AUTOSAR XML (schema 00046)
package /ComponentTypes
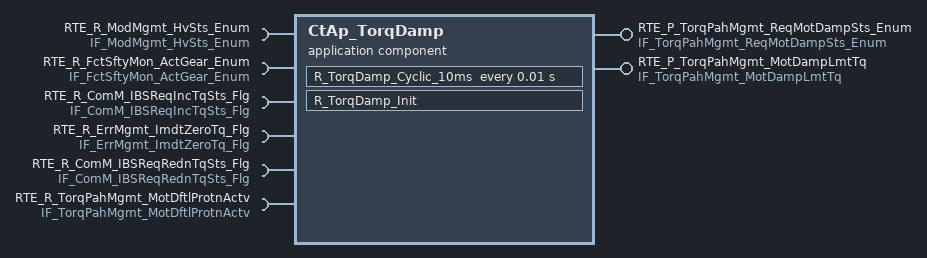
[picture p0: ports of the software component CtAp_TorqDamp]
  application sw component type CtAp_TorqDamp
    provide port RTE_P_TorqPahMgmt_ReqMotDampSts_Enum: nonqueued-sender-com-spec{data-element=tec_TorqPahMgmt_ReqMotDampSts_Enum, init-value=0}, provided-interface=IF_TorqPahMgmt_ReqMotDampSts_Enum
    require port RTE_R_ModMgmt_HvSts_Enum: nonqueued-receiver-com-spec{data-element=tec_ModMgmt_HvSts_Enum, filter=data-filter-type=ALWAYS, init-value=0}, required-interface=IF_ModMgmt_HvSts_Enum
    require port RTE_R_FctSftyMon_ActGear_Enum: nonqueued-receiver-com-spec{data-element=tec_FctSftyMon_ActGear_Enum, filter=data-filter-type=ALWAYS, init-value=0}, required-interface=IF_FctSftyMon_ActGear_Enum
    provide port RTE_P_TorqPahMgmt_MotDampLmtTq: nonqueued-sender-com-spec{data-element=tec_TorqPahMgmt_MotDampLmtTq, init-value=0}, provided-interface=IF_TorqPahMgmt_MotDampLmtTq
    4 x require port:
      RTE_R_ComM_IBSReqIncTqSts_Flg: nonqueued-receiver-com-spec{data-element=tec_ComM_IBSReqIncTqSts_Flg, filter=data-filter-type=ALWAYS, init-value=0}, required-interface=IF_ComM_IBSReqIncTqSts_Flg
      RTE_R_ErrMgmt_ImdtZeroTq_Flg: nonqueued-receiver-com-spec{data-element=tec_ErrMgmt_ImdtZeroTq_Flg, filter=data-filter-type=ALWAYS, init-value=0}, required-interface=IF_ErrMgmt_ImdtZeroTq_Flg
      RTE_R_ComM_IBSReqRednTqSts_Flg: nonqueued-receiver-com-spec{data-element=tec_ComM_IBSReqRednTqSts_Flg, filter=data-filter-type=ALWAYS, init-value=0}, required-interface=IF_ComM_IBSReqRednTqSts_Flg
      RTE_R_TorqPahMgmt_MotDftlProtnActv: nonqueued-receiver-com-spec{data-element=tec_TorqPahMgmt_MotDftlProtnActv, filter=data-filter-type=ALWAYS, init-value=0}, required-interface=IF_TorqPahMgmt_MotDftlProtnActv
    behavior CtAp_TorqDamp_InternalBehavior
      timing event TMT_R_TorqDamp_Cyclic_10ms: start-on-event=R_TorqDamp_Cyclic_10ms, period=0.01
      init event CtAp_TorqDamp_InitEvent: start-on-event=R_TorqDamp_Init
      runnable R_TorqDamp_Cyclic_10ms
        data-receive-point-by-arguments:
          6 x access:
            REC_RTE_R_FctSftyMon_ActGear_Enum_tec_FctSftyMon_ActGear_Enum: accessed-variable=RTE_R_FctSftyMon_ActGear_Enum.tec_FctSftyMon_ActGear_Enum
            REC_RTE_R_ModMgmt_HvSts_Enum_tec_ModMgmt_HvSts_Enum: accessed-variable=RTE_R_ModMgmt_HvSts_Enum.tec_ModMgmt_HvSts_Enum
            REC_RTE_R_ComM_IBSReqIncTqSts_Flg_tec_ComM_IBSReqIncTqSts_Flg: accessed-variable=RTE_R_ComM_IBSReqIncTqSts_Flg.tec_ComM_IBSReqIncTqSts_Flg
            REC_RTE_R_ComM_IBSReqRednTqSts_Flg_tec_ComM_IBSReqRednTqSts_Flg: accessed-variable=RTE_R_ComM_IBSReqRednTqSts_Flg.tec_ComM_IBSReqRednTqSts_Flg
            REC_RTE_R_ErrMgmt_ImdtZeroTq_Flg_tec_ErrMgmt_ImdtZeroTq_Flg: accessed-variable=RTE_R_ErrMgmt_ImdtZeroTq_Flg.tec_ErrMgmt_ImdtZeroTq_Flg
            REC_RTE_R_TorqPahMgmt_MotDftlProtnActv_tec_TorqPahMgmt_MotDftlProtnActv: accessed-variable=RTE_R_TorqPahMgmt_MotDftlProtnActv.tec_TorqPahMgmt_MotDftlProtnActv
        data-send-points:
          access SEND_RTE_P_TorqPahMgmt_ReqMotDampSts_Enum_tec_TorqPahMgmt_ReqMotDampSts_Enum: accessed-variable=RTE_P_TorqPahMgmt_ReqMotDampSts_Enum.tec_TorqPahMgmt_ReqMotDampSts_Enum
          access SEND_RTE_P_TorqPahMgmt_MotDampLmtTq_tec_TorqPahMgmt_MotDampLmtTq: accessed-variable=RTE_P_TorqPahMgmt_MotDampLmtTq.tec_TorqPahMgmt_MotDampLmtTq
      runnable R_TorqDamp_Init
  swc implementation CtAp_TorqDamp_Implementation: behavior=CtAp_TorqDamp_InternalBehavior
